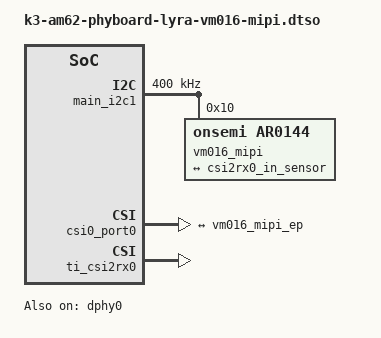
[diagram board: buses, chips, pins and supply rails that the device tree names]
// SPDX-License-Identifier: GPL-2.0
/*
 * Copyright (C) 2022 PHYTEC Messtechnik GmbH
 * Author: Wadim Egorov <w.egorov@phytec.de>
 */

/dts-v1/;
/plugin/;

#include <dt-bindings/gpio/gpio.h>

&{/} {
	clk_cam: clk-cam {
		compatible = "fixed-clock";
		#clock-cells = <0>;
		clock-frequency = <27000000>;
	};
};

&main_i2c1 {
	pinctrl-names = "default";
	pinctrl-0 = <&main_i2c1_pins_default>;
	clock-frequency = <400000>;
	#address-cells = <1>;
	#size-cells = <0>;
	status = "okay";

	vm016_mipi: vm016-mipi@10 {
		compatible = "onsemi,ar0144";
		reg = <0x10>;

		clocks = <&clk_cam>;
		clock-names = "ext";

		port {
			vm016_mipi_ep: endpoint {
				remote-endpoint = <&csi2rx0_in_sensor>;
				clock-lanes = <0>;
				data-lanes = <1 2>;
				clock-noncontinuous = <1>;
				bus-type = <4>; /* MIPI_CSI2_DPHY */
				link-frequencies = /bits/ 64 <222750000>;
			};
		};
	};
};

&csi0_port0 {
	status = "okay";

	csi2rx0_in_sensor: endpoint {
		remote-endpoint = <&vm016_mipi_ep>;
		bus-type = <4>; /* CSI2 DPHY. */
		clock-lanes = <0>;
		data-lanes = <1 2>;
	};
};

&dphy0 {
	status = "okay";
};

&ti_csi2rx0 {
	status = "okay";
};
